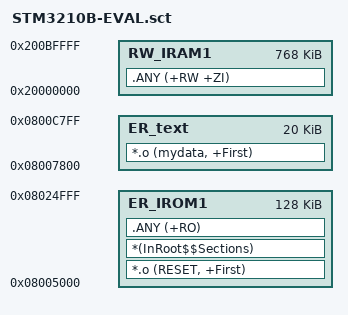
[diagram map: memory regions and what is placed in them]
; *************************************************************
; *** Scatter-Loading Description File generated by uVision ***
; *************************************************************

;// 19K 0x4C00
;#define  mtext_start               0x08004C00	/* Passwd */
;#define  mtext_size                0x0020   /* 32B */
;#define  etext_start               0x08004C20	/* erase Code */
;#define  etext_size                0x0200   /* 512B */
;#define  mdata_start               0x08004E20	/* Data */
;#define  mdata_size                0x0080   /* 128B */

;LR_IROM2 0x08000000 0x00005000  {
;  ER_IROM2 0x08000000 0x00005000  {  ; load address = execution address
;   .ANY (+RO)
;  }
;}
LR_IROM1 0x08005000 0x00020000  {    ; load region size_region
;  ER_IROM2 0x08003000 0x00002000  {  ; load address = execution address
;    *.o (mycode, +First)
;	.ANY (.boot)
;  }
  ER_IROM1 0x08005000 0x00020000  {  ; load address = execution address
   *.o (RESET, +First)
   *(InRoot$$Sections)
   .ANY (+RO)
  }
  RW_IRAM1 0x20000000 0x0000C0000  {  ; RW data //20K
   .ANY (+RW +ZI)
  }
}

LR_text 0x08007800 0x5000  {    ; load region size_region 30K
  ER_text 0x08007800 0x5000  { ; /* Passwd 20K */
;  ER_text 0x08005008 0x4FF8  { ; /* Passwd 1024B */
;   .ANY (.boot)
   *.o  (mydata, +First)
  }
}


